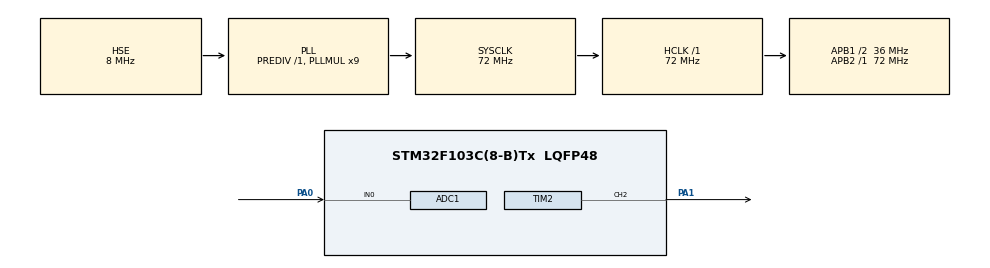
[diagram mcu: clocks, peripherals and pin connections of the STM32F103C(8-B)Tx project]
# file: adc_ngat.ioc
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ADC1.Channel-0\#ChannelRegularConversion=ADC_CHANNEL_0
ADC1.ContinuousConvMode=ENABLE
ADC1.NbrOfConversionFlag=1
ADC1.Rank-0\#ChannelRegularConversion=1
ADC1.SamplingTime-0\#ChannelRegularConversion=ADC_SAMPLETIME_1CYCLE_5
ADC1.master=1
Mcu.Family=STM32F1
Mcu.Name=STM32F103C(8-B)Tx
Mcu.Package=LQFP48
NVIC.ADC1_2_IRQn=true\:0\:0\:false\:false\:true\:true\:true
NVIC.PriorityGroup=NVIC_PRIORITYGROUP_4
PA0-WKUP.Signal=ADCx_IN0
PA1.Signal=S_TIM2_CH2
PA13.Mode=Serial_Wire
PA13.Signal=SYS_JTMS-SWDIO
PA14.Mode=Serial_Wire
PA14.Signal=SYS_JTCK-SWCLK
PD0-OSC_IN.Mode=HSE-External-Oscillator
PD0-OSC_IN.Signal=RCC_OSC_IN
PD1-OSC_OUT.Mode=HSE-External-Oscillator
PD1-OSC_OUT.Signal=RCC_OSC_OUT
ProjectManager.HeapSize=0x200
ProjectManager.StackSize=0x400
ProjectManager.TargetToolchain=MDK-ARM V5.32
RCC.ADCPresc=RCC_ADCPCLK2_DIV6
RCC.AHBFreq_Value=72000000
RCC.APB1CLKDivider=RCC_HCLK_DIV2
RCC.APB1Freq_Value=36000000
RCC.APB1TimFreq_Value=72000000
RCC.APB2Freq_Value=72000000
RCC.APB2TimFreq_Value=72000000
RCC.HCLKFreq_Value=72000000
RCC.PLLMUL=RCC_PLL_MUL9
RCC.PLLSourceVirtual=RCC_PLLSOURCE_HSE
RCC.SYSCLKFreq_VALUE=72000000
RCC.SYSCLKSource=RCC_SYSCLKSOURCE_PLLCLK
RCC.USBFreq_Value=72000000
SH.ADCx_IN0.0=ADC1_IN0,IN0
SH.S_TIM2_CH2.0=TIM2_CH2,PWM Generation2 CH2
TIM2.Channel-PWM\ Generation2\ CH2=TIM_CHANNEL_2
TIM2.Period=999
TIM2.Prescaler=35
VP_TIM2_VS_ClockSourceINT.Mode=Internal
board=custom

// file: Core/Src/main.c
/* USER CODE BEGIN Header */
/**
  ******************************************************************************
  * @file           : main.c
  * @brief          : Main program body
  ******************************************************************************
  * @attention
  *
  * <h2><center>&copy; Copyright (c) 2021 STMicroelectronics.
  * All rights reserved.</center></h2>
  *
  * This software component is licensed by ST under BSD 3-Clause license,
  * the "License"; You may not use this file except in compliance with the
  * License. You may obtain a copy of the License at:
  *                        opensource.org/licenses/BSD-3-Clause
  *
  ******************************************************************************
  */
/* USER CODE END Header */
#include "main.h"
#include "adc.h"
#include "tim.h"
#include "gpio.h"

void SystemClock_Config(void);

/* USER CODE BEGIN 0 */
#define MAX_SAMPLE 30
typedef struct
{
	uint8_t index;
	uint8_t flag;
	uint32_t val;
	uint32_t tAdc;
	uint32_t sum;
}ADC_TypeDef_t;

ADC_TypeDef_t adc;

void HAL_ADC_ConvCpltCallback(ADC_HandleTypeDef *hadc)
{
	adc.sum += HAL_ADC_GetValue(hadc);
	adc.index++;
	if(adc.index == (MAX_SAMPLE-1))
	{
		adc.val = adc.sum/MAX_SAMPLE;
		adc.sum = 0;
		adc.flag = 1;
		adc.index = 0;
	}
	HAL_ADC_Stop_IT(hadc);
}

/* USER CODE END 0 */

int main(void)
{

  /* MCU Configuration--------------------------------------------------------*/

  /* Reset of all peripherals, Initializes the Flash interface and the Systick. */
  HAL_Init();

  /* Configure the system clock */
  SystemClock_Config();

  /* Initialize all configured peripherals */
  MX_GPIO_Init();
  MX_ADC1_Init();
  MX_TIM2_Init();
  /* USER CODE BEGIN 2 */
	HAL_ADCEx_Calibration_Start(&hadc1);
	HAL_TIM_PWM_Start(&htim2,TIM_CHANNEL_2);
  /* USER CODE END 2 */

  /* Infinite loop */
  while (1)
  {

    /* USER CODE BEGIN 3 */
		if(HAL_GetTick() - adc.tAdc >= 10)
		{
			HAL_ADC_Start_IT(&hadc1);
			adc.tAdc = HAL_GetTick();
		}
		if(adc.flag)
		{
			adc.flag = 0;
		}
		__HAL_TIM_SET_COMPARE(&htim2,TIM_CHANNEL_2,(100*adc.val)/4096);
  }
  /* USER CODE END 3 */
}

void SystemClock_Config(void)
{
  RCC_OscInitTypeDef RCC_OscInitStruct = {0};
  RCC_ClkInitTypeDef RCC_ClkInitStruct = {0};
  RCC_PeriphCLKInitTypeDef PeriphClkInit = {0};

  /** Initializes the RCC Oscillators according to the specified parameters
  * in the RCC_OscInitTypeDef structure.
  */
  RCC_OscInitStruct.OscillatorType = RCC_OSCILLATORTYPE_HSE;
  RCC_OscInitStruct.HSEState = RCC_HSE_ON;
  RCC_OscInitStruct.HSEPredivValue = RCC_HSE_PREDIV_DIV1;
  RCC_OscInitStruct.HSIState = RCC_HSI_ON;
  RCC_OscInitStruct.PLL.PLLState = RCC_PLL_ON;
  RCC_OscInitStruct.PLL.PLLSource = RCC_PLLSOURCE_HSE;
  RCC_OscInitStruct.PLL.PLLMUL = RCC_PLL_MUL9;
  if (HAL_RCC_OscConfig(&RCC_OscInitStruct) != HAL_OK)
  {
    Error_Handler();
  }
  /** Initializes the CPU, AHB and APB buses clocks
  */
  RCC_ClkInitStruct.ClockType = RCC_CLOCKTYPE_HCLK|RCC_CLOCKTYPE_SYSCLK
                              |RCC_CLOCKTYPE_PCLK1|RCC_CLOCKTYPE_PCLK2;
  RCC_ClkInitStruct.SYSCLKSource = RCC_SYSCLKSOURCE_PLLCLK;
  RCC_ClkInitStruct.AHBCLKDivider = RCC_SYSCLK_DIV1;
  RCC_ClkInitStruct.APB1CLKDivider = RCC_HCLK_DIV2;
  RCC_ClkInitStruct.APB2CLKDivider = RCC_HCLK_DIV1;

  if (HAL_RCC_ClockConfig(&RCC_ClkInitStruct, FLASH_LATENCY_2) != HAL_OK)
  {
    Error_Handler();
  }
  PeriphClkInit.PeriphClockSelection = RCC_PERIPHCLK_ADC;
  PeriphClkInit.AdcClockSelection = RCC_ADCPCLK2_DIV6;
  if (HAL_RCCEx_PeriphCLKConfig(&PeriphClkInit) != HAL_OK)
  {
    Error_Handler();
  }
}

void Error_Handler(void)
{
  __disable_irq();
  while (1)
  {
  }
}

/************************ (C) COPYRIGHT STMicroelectronics *****END OF FILE****/
